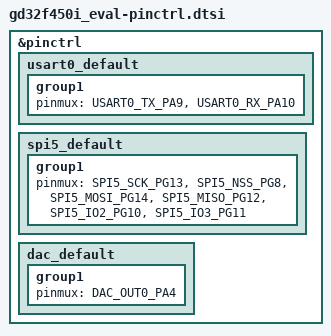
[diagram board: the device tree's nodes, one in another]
/*
 * Copyright (c) 2021, Teslabs Engineering S.L.
 * SPDX-License-Identifier: Apache-2.0
 */

#include <dt-bindings/pinctrl/gd32f450i(g-i-k)xx-pinctrl.h>

&pinctrl {
	usart0_default: usart0_default {
		group1 {
			pinmux = <USART0_TX_PA9>, <USART0_RX_PA10>;
		};
	};

	spi5_default: spi5_default {
		group1 {
			pinmux = <SPI5_SCK_PG13>,  <SPI5_NSS_PG8>,
				 <SPI5_MOSI_PG14>, <SPI5_MISO_PG12>,
				 <SPI5_IO2_PG10>,  <SPI5_IO3_PG11>;
		};
	};

	dac_default: dac_default {
		group1 {
			pinmux = <DAC_OUT0_PA4>;
		};
	};
};
